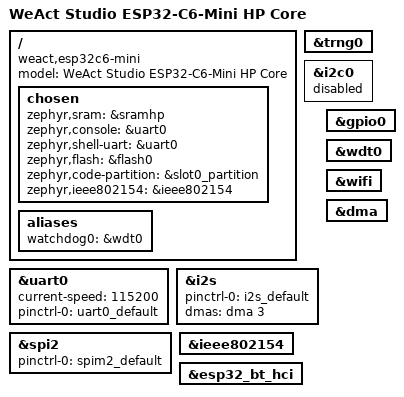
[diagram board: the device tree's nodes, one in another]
/*
 * Copyright (c) 2025 Siratul Islam
 *
 * SPDX-License-Identifier: Apache-2.0
 */

/dts-v1/;

#include <espressif/esp32c6/esp32c6_wroom_n4.dtsi>
#include "esp32c6_supermini_hpcore-pinctrl.dtsi"
#include <zephyr/dt-bindings/input/input-event-codes.h>
#include <espressif/partitions_0x0_default.dtsi>

/ {
	model = "WeAct Studio ESP32-C6-Mini HP Core";
	compatible = "weact,esp32c6-mini";

	chosen {
		zephyr,sram = &sramhp;
		zephyr,console = &uart0;
		zephyr,shell-uart = &uart0;
		zephyr,flash = &flash0;
		zephyr,code-partition = &slot0_partition;
		zephyr,ieee802154 = &ieee802154;
	};

	aliases {
		watchdog0 = &wdt0;
	};
};

&uart0 {
	status = "okay";
	current-speed = <115200>;
	pinctrl-0 = <&uart0_default>;
	pinctrl-names = "default";
};

&trng0 {
	status = "okay";
};

&i2c0 {
	status = "disabled";
};

&i2s {
	pinctrl-0 = <&i2s_default>;
	pinctrl-names = "default";
	status = "okay";

	dmas = <&dma 3>;
	dma-names = "tx";
};

&spi2 {
	#address-cells = <1>;
	#size-cells = <0>;
	status = "okay";
	pinctrl-0 = <&spim2_default>;
	pinctrl-names = "default";
};

&gpio0 {
	status = "okay";
};

&wdt0 {
	status = "okay";
};

&wifi {
	status = "okay";
};

&ieee802154 {
	status = "okay";
};

&esp32_bt_hci {
	status = "okay";
};

&dma {
	status = "okay";
};
